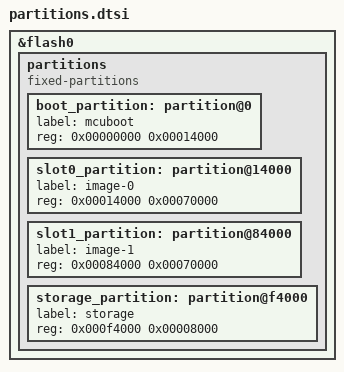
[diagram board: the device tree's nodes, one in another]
/*
 * OPTIONAL (OTA build) — shared MCUboot flash layout, included by both
 * ota.overlay and mcuboot.overlay so you size the partitions in ONE place.
 * slot0 and slot1 MUST be equal size. Example below is for a 1 MB flash.
 */

&flash0 {
	/delete-node/ partitions;

	partitions {
		compatible = "fixed-partitions";
		#address-cells = <1>;
		#size-cells = <1>;

		boot_partition: partition@0 {
			label = "mcuboot";
			reg = <0x00000000 0x00014000>;   /* 80 kB */
		};
		slot0_partition: partition@14000 {
			label = "image-0";
			reg = <0x00014000 0x00070000>;   /* 448 kB */
		};
		slot1_partition: partition@84000 {
			label = "image-1";
			reg = <0x00084000 0x00070000>;   /* 448 kB */
		};
		storage_partition: partition@f4000 {
			label = "storage";
			reg = <0x000f4000 0x00008000>;   /* 32 kB */
		};
	};
};
